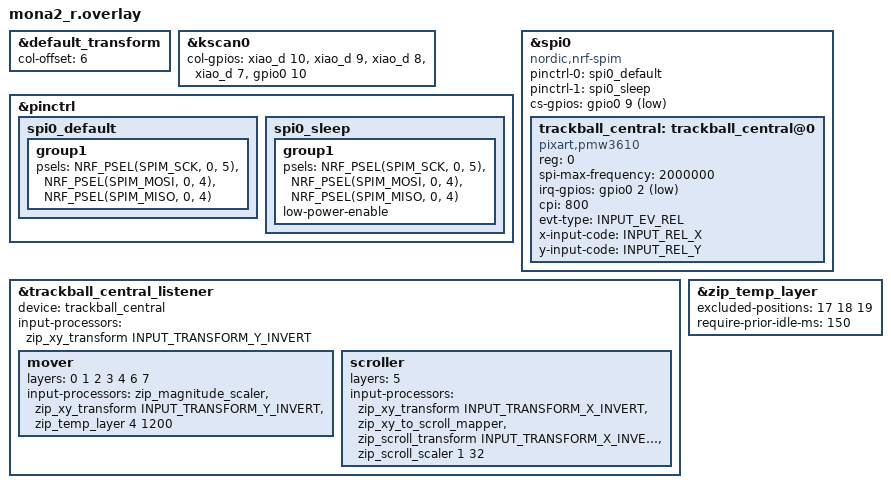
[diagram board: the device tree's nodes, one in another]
#include "mona2.dtsi"
#include <input/processors.dtsi>
#include <zephyr/dt-bindings/input/input-event-codes.h>


&default_transform {
    col-offset = <6>;
};

&kscan0 {
        col-gpios
            = <&xiao_d 10 GPIO_ACTIVE_HIGH>
            , <&xiao_d 9 GPIO_ACTIVE_HIGH> 
            , <&xiao_d 8 GPIO_ACTIVE_HIGH> 
            , <&xiao_d 7 GPIO_ACTIVE_HIGH> 
            , <&gpio0 10 GPIO_ACTIVE_HIGH>
            ;
};


&pinctrl {
    spi0_default: spi0_default {    //通常時(SPI通信中)のピン構成
        group1 {
            psels = <NRF_PSEL(SPIM_SCK, 0, 5)>, //P0.05を指定(SCLK)
                <NRF_PSEL(SPIM_MOSI, 0, 4)>,    //P0.04を指定(SDIOだからMOSI,MISO両方の役割を担う)
                <NRF_PSEL(SPIM_MISO, 0, 4)>;
        };
    };

    spi0_sleep: spi0_sleep {    //スリープ時のピン構成(省電力)
        group1 {
            psels = <NRF_PSEL(SPIM_SCK, 0, 5)>,
                <NRF_PSEL(SPIM_MOSI, 0, 4)>,
                <NRF_PSEL(SPIM_MISO, 0, 4)>;
            low-power-enable;
        };
    };
};


&spi0 {
    status = "okay";
    compatible = "nordic,nrf-spim"; //マイコンがnRFシリーズ
    pinctrl-0 = <&spi0_default>;
    pinctrl-1 = <&spi0_sleep>;
    pinctrl-names = "default", "sleep";
    cs-gpios = <&gpio0 9 GPIO_ACTIVE_LOW>;  //P0.09を指定(CS)

    trackball_central: trackball_central@0 {
        status = "okay";
        compatible = "pixart,pmw3610";  //トラボセンサ用のドライバとバインド
        reg = <0>;
        spi-max-frequency = <2000000>;
        irq-gpios = <&gpio0 2 (GPIO_ACTIVE_LOW | GPIO_PULL_UP)>; //P0.02を指定(MOTION)
        cpi = <800>;
        //swap-xy;
        //invert-x; //COROPIT版ではコメントアウトを外す
        //invert-y; //COROPIT版ではコメントアウトを外す
        evt-type = <INPUT_EV_REL>;
        x-input-code = <INPUT_REL_X>;
        y-input-code = <INPUT_REL_Y>;
    };
};


// Overrides for the input listener node
&trackball_central_listener {
    status = "okay";
    device = <&trackball_central>;
    input-processors = <&zip_xy_transform INPUT_TRANSFORM_Y_INVERT>;  // フォールバック（mover/scroller が全レイヤーを覆う限り実行されない）

    mover {
        layers = <0 1 2 3 4 6 7>;   // SCROLL(5) 以外すべて
        input-processors =
            <&zip_magnitude_scaler>,                            // 旧実装同様、生の値に倍率適用
            <&zip_xy_transform INPUT_TRANSFORM_Y_INVERT>,       // Y軸反転(親のは子マッチ時に実行されないためここに置く)
            <&zip_temp_layer 4 1200>;   // 旧: automouse-layer=4, TIMEOUT=1200ms
    };

    scroller {
        layers = <5>;               // 旧 scroll-layers=<5> に合わせ 3→5 に変更
        input-processors =
            <&zip_xy_transform INPUT_TRANSFORM_X_INVERT>,       //X軸反転
            <&zip_xy_to_scroll_mapper>,                         //スクロールモードに変更
            <&zip_scroll_transform INPUT_TRANSFORM_X_INVERT>,   //スクロールのX軸反転
            <&zip_scroll_scaler 1 32>;                          //旧実効値: 0.5倍 ÷ SCROLL_TICK 16 = 1/32
    };
};

// zip_temp_layer の誤発動対策（MOUSE_AUTO層の click(17) / mo5(18) / MB2(19) は
// 押してもレイヤー解除しない。旧 MOVEMENT_THRESHOLD=5 の代替として、直前の
// キー入力から150ms以上経過していないと発火しないようにする）
&zip_temp_layer {
    excluded-positions = <17 18 19>;
    require-prior-idle-ms = <150>;
};
